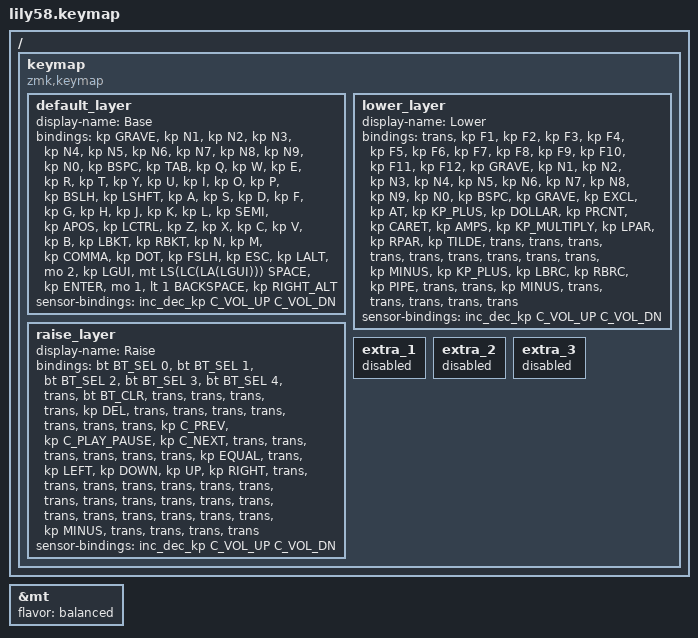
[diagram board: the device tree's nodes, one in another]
/*
 * Copyright (c) 2020 The ZMK Contributors
 *
 * SPDX-License-Identifier: MIT
 */

#include <behaviors.dtsi>
#include <dt-bindings/zmk/keys.h>
#include <dt-bindings/zmk/bt.h>
#include <dt-bindings/zmk/ext_power.h>

&mt { flavor = "balanced"; };

/ {
    keymap {
        compatible = "zmk,keymap";

        default_layer {
// ------------------------------------------------------------------------------------------------------------
// |   `   |  1  |  2  |  3   |  4   |  5   |                   |  6   |  7    |  8    |  9   |   0   | BKSP  |
// |  TAB  |  Q  |  W  |  E   |  R   |  T   |                   |  Y   |  U    |  I    |  O   |   P   |   \   |
// | SHIFT |  A  |  S  |  D   |  F   |  G   |                   |  H   |  J    |  K    |  L   |   ;   |   '   |
// | CTRL  |  Z  |  X  |  C   |  V   |  B   |   "["  |  |  "]"  |  N   |  M    |  ,    |  .   |   /   |   ESC |
//                     | LALT | RSE  | LGUI |  SPACE |  | ENTER | LWR  | BKSP   | RALT   |
            display-name = "Base";
            bindings = <
&kp GRAVE &kp N1 &kp N2 &kp N3   &kp N4   &kp N5                                       &kp N6 &kp N7   &kp N8    &kp N9  &kp N0   &kp BSPC
&kp TAB   &kp Q  &kp W  &kp E    &kp R    &kp T                                        &kp Y  &kp U    &kp I     &kp O   &kp P    &kp BSLH
&kp LSHFT &kp A  &kp S  &kp D    &kp F    &kp G                                        &kp H  &kp J    &kp K     &kp L   &kp SEMI &kp APOS
&kp LCTRL &kp Z  &kp X  &kp C    &kp V    &kp B  &kp LBKT                    &kp RBKT  &kp N  &kp M    &kp COMMA &kp DOT &kp FSLH &kp ESC
                        &kp LALT &mo 2  &kp LGUI &mt LS(LC(LA(LGUI))) SPACE  &kp ENTER &mo 1 &lt 1 BACKSPACE  &kp RIGHT_ALT
            >;

            sensor-bindings = <&inc_dec_kp C_VOL_UP C_VOL_DN>;
        };

        lower_layer {
// ------------------------------------------------------------------------------------------------------------
// |       |     |     |      |      |      |                   |      |       |       |      |       |       |
// |   `   |  1  |  2  |  3   |  4   |  5   |                   |  6   |   7   |   8   |  9   |   0   |       |
// |   `   |  !  |  @  |  +   |  $   |  %   |                   |  ^   |  &    |  *    |  (   |   )   |   ~   |
// |       |     |     |      |      |      |        |  |       |      |  _    |  +    |  {   |   }   |  "|"  |
//                     |      |      |      |    -   |  |       |      |       |       |
            display-name = "Lower";
            bindings = <
&trans    &kp F1    &kp F2   &kp F3    &kp F4       &kp F5                            &kp F6    &kp F7    &kp F8          &kp F9    &kp F10   &kp F11   &kp F12
&kp GRAVE    &kp N1    &kp N2   &kp N3    &kp N4       &kp N5                            &kp N6    &kp N7    &kp N8          &kp N9    &kp N0    &kp BSPC
&kp GRAVE    &kp EXCL  &kp AT   &kp KP_PLUS  &kp DOLLAR   &kp PRCNT                         &kp CARET &kp AMPS  &kp KP_MULTIPLY &kp LPAR  &kp RPAR  &kp TILDE
&trans       &trans    &trans   &trans    &trans       &trans     &trans   &trans        &trans    &kp MINUS &kp KP_PLUS     &kp LBRC  &kp RBRC  &kp PIPE
                                          &trans       &trans     &kp MINUS   &trans &trans    &trans    &trans    &trans
            >;

            sensor-bindings = <&inc_dec_kp C_VOL_UP C_VOL_DN>;
        };

        raise_layer {
// ------------------------------------------------------------------------------------------------------------
// |  BT1  | BT2 | BT3 |  BT4 |  BT5 |      |                   | BTCLR|       |       |      |       |  DEL  |
// |  F1   |  F2 |  F3 |  F4  |  F5  |  F6  |                   |  F7  |  F8   |  F9   |  F10 |  F11  |  F12  |
// |   F1  |  F2 |  F3 |  F4  |  F5  |  F6  |                   |      |   <-  |   v   |  ^   |  ->   |       |
// |   F7  |  F8 |  F9 |  F10 |  F11 |  F12 |        |  |       |  +   |   -   |   =   |  [   |   ]   |   \   |
//                     |      |      |      |        |  |       |      |       |       |
            display-name = "Raise";
            bindings = <
&bt BT_SEL 0 &bt BT_SEL 1  &bt BT_SEL 2   &bt BT_SEL 3    &bt BT_SEL 4  &trans                       &bt BT_CLR    &trans     &trans          &trans    &trans   &kp DEL
&trans    &trans &trans &trans  &trans  &trans                       &trans      &kp C_PREV  &kp C_PLAY_PAUSE  &kp C_NEXT     &trans &trans 
&trans    &trans &trans &trans  &kp EQUAL  &trans                       &kp LEFT    &kp DOWN    &kp UP            &kp RIGHT      &trans &trans 
&trans    &trans &trans &trans  &trans  &trans   &trans              &trans      &trans      &trans            &trans         &trans &trans &trans 
                        &trans  &trans  &trans   &kp MINUS           &trans      &trans      &trans            &trans
            >;

            sensor-bindings = <&inc_dec_kp C_VOL_UP C_VOL_DN>;
        };

        extra_1 {
            status = "reserved";
        };

        extra_2 {
            status = "reserved";
        };

        extra_3 {
            status = "reserved";
        };
    };
};
